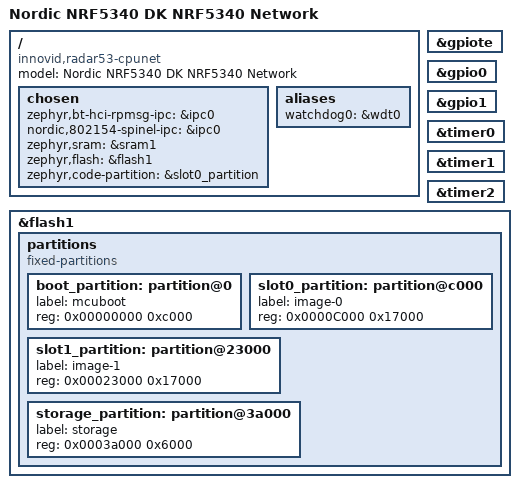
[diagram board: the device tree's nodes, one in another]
/dts-v1/;
#include <nordic/nrf5340_cpunet_qkaa.dtsi>
#include "radar53_cpunet-pinctrl.dtsi"

/ {
	model = "Nordic NRF5340 DK NRF5340 Network";
	compatible = "innovid,radar53-cpunet";

	chosen {
		zephyr,bt-hci-rpmsg-ipc = &ipc0;
		nordic,802154-spinel-ipc = &ipc0;
		zephyr,sram = &sram1;
		zephyr,flash = &flash1;
		zephyr,code-partition = &slot0_partition;
		// zephyr,ieee802154 = &ieee802154;
	};




	/* These aliases are provided for compatibility with samples */
	aliases {
		watchdog0 = &wdt0;
	};
};

&gpiote {
	status = "okay";
};

&gpio0 {
	status = "okay";
};

&gpio1 {
	status = "okay";
};


&timer0 {
	status = "okay";
};

&timer1 {
	status = "okay";
};

&timer2 {
	status = "okay";
};

&flash1 {

	partitions {
		compatible = "fixed-partitions";
		#address-cells = <1>;
		#size-cells = <1>;

		boot_partition: partition@0 {
			label = "mcuboot";
			reg = <0x00000000 0xc000>;
		};
		slot0_partition: partition@c000 {
			label = "image-0";
			reg = <0x0000C000 0x17000>;
		};
		slot1_partition: partition@23000 {
			label = "image-1";
			reg = <0x00023000 0x17000>;
		};
		storage_partition: partition@3a000 {
			label = "storage";
			reg = <0x0003a000 0x6000>;
		};
	};
};

// &ieee802154 {
// 	status = "okay";
// };

/* Include shared RAM configuration file */
#include "nrf5340_shared_sram_planning_conf.dts"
